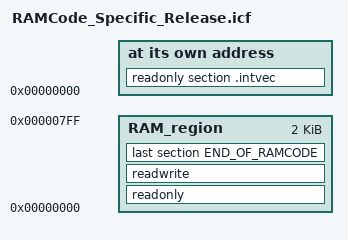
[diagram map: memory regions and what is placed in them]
//*********************************************************************
//*                SEGGER MICROCONTROLLER GmbH & Co KG                *
//*        Solutions for real time microcontroller applications       *
//*********************************************************************
//*                                                                   *
//*      (C) 2010 SEGGER Microcontroller GmbH & Co. KG                *
//*                  www.segger.com                                   *
//*                                                                   *
//*********************************************************************
//
//---------------------------------------------------------------------
//File   : RAMCodeV2.icf
//Purpose: Linker file for RAMCode V2. Do not change!
//-------- END-OF-HEADER ----------------------------------------------
//

define memory mem with size = 4G;
define region RAM_region = mem:[from 0x00000000 to 0x000007ff];

initialize by copy { readwrite };
do not initialize  { section .noinit };

place at address mem:0x00000000    { readonly section .intvec };

place in RAM_region   { readonly, readwrite, last section END_OF_RAMCODE};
